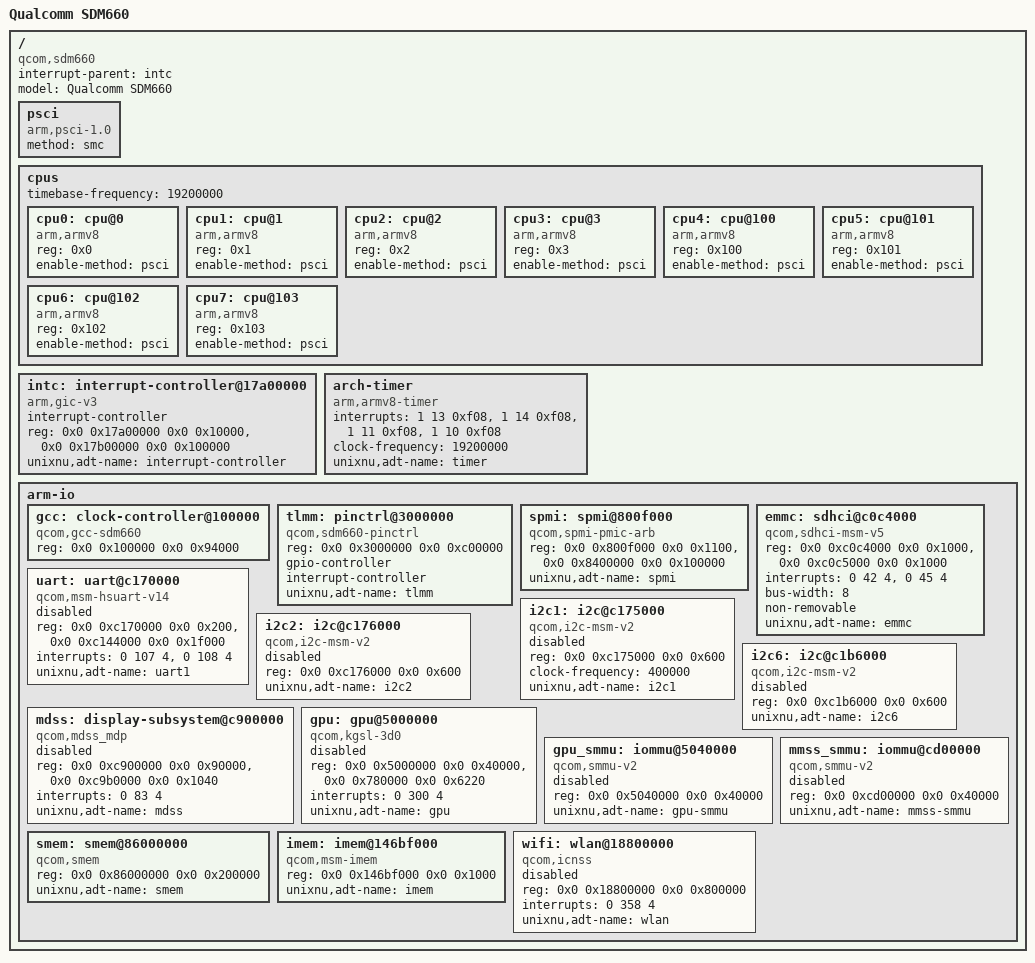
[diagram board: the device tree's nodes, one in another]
// SPDX-License-Identifier: BSD-3-Clause
//
// Qualcomm SDM660 (Snapdragon 660) shared hardware description.
//
// Addresses and interrupt numbers come from the stock OPPO R11 device tree
// (UniXNU-r11/inputs/r11-stock.dts, extracted from the OTA boot image) and the
// SDM660 CLO kernel sources. Register windows are the ones XNU drivers need;
// this is not a full Linux description.
//
// Cell width: every bus below uses two address cells and two size cells, and a
// `ranges` that covers the whole translated window, as the ADT generator expects.

/ {
    #address-cells = <2>;
    #size-cells = <2>;
    interrupt-parent = <&intc>;

    compatible = "qcom,sdm660";
    model = "Qualcomm SDM660";

    psci {
        compatible = "arm,psci-1.0", "arm,psci";
        method = "smc";
    };

    cpus {
        #address-cells = <1>;
        #size-cells = <0>;
        // XNU's ADT translation requires an explicit ranges property on any node
        // that declares #address-cells. Empty means the identity mapping, which
        // is what the cpu@N reg values (plain affinity numbers) already assume.
        ranges;
        // No unixnu,adt-name on the cpu@N children: the generator turns every
        // exported node into a child of /arm-io and rewrites its reg as a
        // physical address minus the arm-io base, so an exported cpu would put an
        // MPIDR affinity (0x0, 0x100, ...) below the 16 MiB base and /arm-io would
        // be rejected. The ADT cpus node is built from these same children.
        // 19.2 MHz XO is the ARM generic timer rate on SDM660.
        timebase-frequency = <19200000>;

        // Cluster 0: Kryo 260 silver (Cortex-A53 class), MPIDR 0x000-0x003.
        cpu0: cpu@0 {
            device_type = "cpu";
            compatible = "arm,armv8";
            reg = <0x0>;
            enable-method = "psci";
        };
        cpu1: cpu@1 {
            device_type = "cpu";
            compatible = "arm,armv8";
            reg = <0x1>;
            enable-method = "psci";
        };
        cpu2: cpu@2 {
            device_type = "cpu";
            compatible = "arm,armv8";
            reg = <0x2>;
            enable-method = "psci";
        };
        cpu3: cpu@3 {
            device_type = "cpu";
            compatible = "arm,armv8";
            reg = <0x3>;
            enable-method = "psci";
        };
        // Cluster 1: Kryo 260 gold (Cortex-A73 class), MPIDR 0x100-0x103.
        cpu4: cpu@100 {
            device_type = "cpu";
            compatible = "arm,armv8";
            reg = <0x100>;
            enable-method = "psci";
        };
        cpu5: cpu@101 {
            device_type = "cpu";
            compatible = "arm,armv8";
            reg = <0x101>;
            enable-method = "psci";
        };
        cpu6: cpu@102 {
            device_type = "cpu";
            compatible = "arm,armv8";
            reg = <0x102>;
            enable-method = "psci";
        };
        cpu7: cpu@103 {
            device_type = "cpu";
            compatible = "arm,armv8";
            reg = <0x103>;
            enable-method = "psci";
        };
    };

    // GICv3: distributor 0x17a00000, redistributors 0x17b00000 (8 x 0x20000).
    intc: interrupt-controller@17a00000 {
        compatible = "arm,gic-v3";
        #interrupt-cells = <3>;
        interrupt-controller;
        #address-cells = <0>;
        ranges;
        reg = <0x0 0x17a00000 0x0 0x10000>,
              <0x0 0x17b00000 0x0 0x100000>;
        unixnu,adt-name = "interrupt-controller";
    };

    arch-timer {
        compatible = "arm,armv8-timer";
        interrupts = <1 13 0xf08>,
                     <1 14 0xf08>,
                     <1 11 0xf08>,
                     <1 10 0xf08>;
        clock-frequency = <19200000>;
        unixnu,adt-name = "timer";
    };

    // Translated windows for the SoC peripherals. DRAM itself stays unmapped;
    // the last two entries exist only because SMEM and IMEM sit inside DRAM and
    // still need a translation of their own.
    //   0x00000000-0x0ff00000  GCC, TLMM, SPMI, USB, SDCC, MDSS, SMMU, GPU clocks
    //   0x17000000-0x19000000  GIC, QTIMER, WCNSS
    //   0x86000000-0x86200000  SMEM (inside DRAM)
    //   0x146b0000-0x146d0000  IMEM (inside DRAM)
    arm-io {
        #address-cells = <2>;
        #size-cells = <2>;
        ranges = <0x0 0x00000000 0x0 0x00000000 0x0 0x0ff00000>,
                 <0x0 0x17000000 0x0 0x17000000 0x0 0x02000000>,
                 <0x0 0x86000000 0x0 0x86000000 0x0 0x00200000>,
                 <0x0 0x146b0000 0x0 0x146b0000 0x0 0x00020000>;

        gcc: clock-controller@100000 {
            compatible = "qcom,gcc-sdm660", "syscon";
            reg = <0x0 0x100000 0x0 0x94000>;
            #clock-cells = <1>;
            #reset-cells = <1>;
            // Not exported to the ADT: arm_io_window() takes the lowest exported
            // register and aligns it down to 16 MiB, and GCC sits at 1 MiB, which
            // would make the arm-io base zero -- the builder refuses that. ABL has
            // already programmed the clocks this early boot needs, so leaving GCC
            // out of the ADT costs DVFS, not bring-up. Revisit once a clock driver
            // exists that can place GCC relative to a non-zero base.
        };

        tlmm: pinctrl@3000000 {
            compatible = "qcom,sdm660-pinctrl";
            reg = <0x0 0x3000000 0x0 0xc00000>;
            gpio-controller;
            #gpio-cells = <2>;
            interrupt-controller;
            #interrupt-cells = <2>;
            unixnu,adt-name = "tlmm";
        };

        spmi: spmi@800f000 {
            compatible = "qcom,spmi-pmic-arb";
            reg = <0x0 0x800f000 0x0 0x1100>,
                  <0x0 0x8400000 0x0 0x100000>;
            #address-cells = <2>;
            ranges;
            #size-cells = <0>;
            unixnu,adt-name = "spmi";
        };

        // Primary eMMC controller (sdhc1). Vendor firmware and the GPT live here.
        emmc: sdhci@c0c4000 {
            compatible = "qcom,sdhci-msm-v5";
            reg = <0x0 0xc0c4000 0x0 0x1000>,
                  <0x0 0xc0c5000 0x0 0x1000>;
            reg-names = "hc", "core";
            interrupts = <0 42 4>, <0 45 4>;
            interrupt-names = "hc_irq", "pwr_irq";
            clock-names = "iface", "core";
            bus-width = <8>;
            non-removable;
            unixnu,adt-name = "emmc";
        };

        // BLSP1 UART1 (ttyMSM0). The stock ABL keeps it disabled and the R11 has
        // no exposed UART pads, so firmware logs travel over the framebuffer.
        uart: uart@c170000 {
            compatible = "qcom,msm-hsuart-v14";
            reg = <0x0 0xc170000 0x0 0x200>,
                  <0x0 0xc144000 0x0 0x1f000>;
            reg-names = "core_mem", "bam_mem";
            interrupts = <0 107 4>, <0 108 4>;
            status = "disabled";
            unixnu,adt-name = "uart1";
        };

        // BLSP1 I2C1: Synaptics S3508 touch at 0x20 (board node adds the sensor).
        i2c1: i2c@c175000 {
            compatible = "qcom,i2c-msm-v2";
            reg = <0x0 0xc175000 0x0 0x600>;
            #address-cells = <1>;
            ranges;
            #size-cells = <0>;
            clock-frequency = <400000>;
            status = "disabled";
            unixnu,adt-name = "i2c1";
        };

        i2c2: i2c@c176000 {
            compatible = "qcom,i2c-msm-v2";
            reg = <0x0 0xc176000 0x0 0x600>;
            #address-cells = <1>;
            ranges;
            #size-cells = <0>;
            status = "disabled";
            unixnu,adt-name = "i2c2";
        };

        i2c6: i2c@c1b6000 {
            compatible = "qcom,i2c-msm-v2";
            reg = <0x0 0xc1b6000 0x0 0x600>;
            #address-cells = <1>;
            ranges;
            #size-cells = <0>;
            status = "disabled";
            unixnu,adt-name = "i2c6";
        };

        // MDSS: MDP plus the DSI PLL/PHY windows the panel driver needs.
        mdss: display-subsystem@c900000 {
            compatible = "qcom,mdss_mdp";
            reg = <0x0 0xc900000 0x0 0x90000>,
                  <0x0 0xc9b0000 0x0 0x1040>;
            reg-names = "mdp", "dsi_pll";
            interrupts = <0 83 4>;
            #address-cells = <2>;
            ranges;
            #size-cells = <1>;
            status = "disabled";
            unixnu,adt-name = "mdss";
        };

        // Adreno 512 (KGSL) and its SMMU.
        gpu: gpu@5000000 {
            compatible = "qcom,kgsl-3d0", "qcom,kgsl-3d";
            reg = <0x0 0x5000000 0x0 0x40000>,
                  <0x0 0x780000 0x0 0x6220>;
            reg-names = "kgsl_3d0_reg_memory", "gmu";
            interrupts = <0 300 4>;
            status = "disabled";
            unixnu,adt-name = "gpu";
        };

        gpu_smmu: iommu@5040000 {
            compatible = "qcom,smmu-v2";
            reg = <0x0 0x5040000 0x0 0x40000>;
            #iommu-cells = <1>;
            status = "disabled";
            unixnu,adt-name = "gpu-smmu";
        };

        mmss_smmu: iommu@cd00000 {
            compatible = "qcom,smmu-v2";
            reg = <0x0 0xcd00000 0x0 0x40000>;
            #iommu-cells = <1>;
            status = "disabled";
            unixnu,adt-name = "mmss-smmu";
        };

        smem: smem@86000000 {
            compatible = "qcom,smem";
            reg = <0x0 0x86000000 0x0 0x200000>;
            unixnu,adt-name = "smem";
        };

        imem: imem@146bf000 {
            compatible = "qcom,msm-imem";
            reg = <0x0 0x146bf000 0x0 0x1000>;
            unixnu,adt-name = "imem";
        };

        // WCN3990 companion over the integrated WLAN block.
        wifi: wlan@18800000 {
            compatible = "qcom,icnss";
            reg = <0x0 0x18800000 0x0 0x800000>;
            interrupts = <0 358 4>;
            status = "disabled";
            unixnu,adt-name = "wlan";
        };
    };
};
